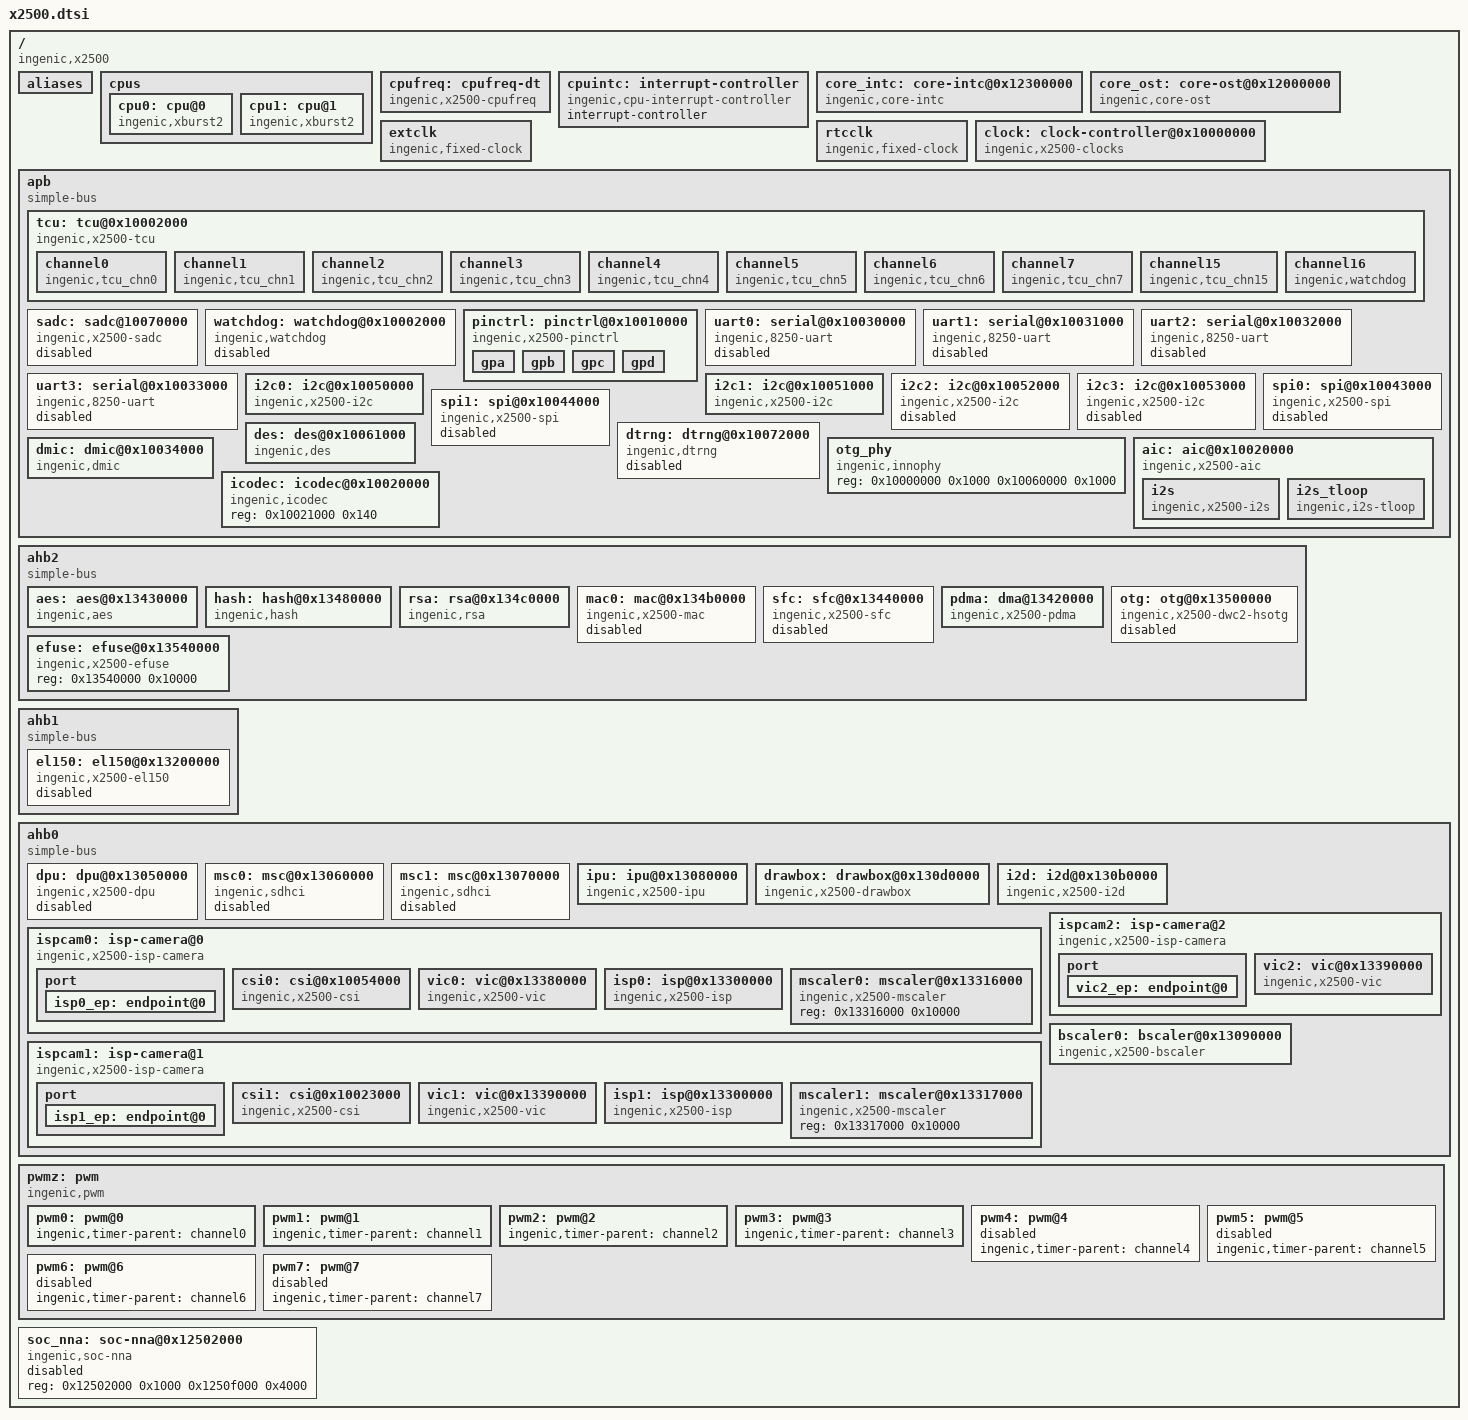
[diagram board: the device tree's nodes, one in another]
#include <dt-bindings/interrupt-controller/x2500-irq.h>
#include <dt-bindings/clock/ingenic-x2500.h>
#include <dt-bindings/clock/ingenic-tcu.h>
#include <dt-bindings/sound/ingenic-baic.h>
#include <dt-bindings/net/ingenic_gmac.h>
#include <dt-bindings/dma/ingenic-pdma.h>

/ {
	#address-cells = <1>;
	#size-cells = <1>;
	compatible = "ingenic,x2500";

	aliases: aliases {
		i2c0 = &i2c0;
		i2c1 = &i2c1;
		i2c2 = &i2c2;
		i2c3 = &i2c3;
		uart0 = &uart0;
		uart1 = &uart1;
		uart2 = &uart2;
		uart3 = &uart3;
		mmc0 = &msc0;
		mmc1 = &msc1;
		mac0 = &mac0;
		spi0 = &spi0;
		spi1 = &spi1;
		bscaler0 = &bscaler0;
	};

	cpus: cpus {
		#address-cells = <1>;
		#size-cells = <0>;

		cpu0: cpu@0 {
			device_type = "cpu";
			compatible = "ingenic,xburst2";
			reg = <0x000>;
			clock-frequency = <1200000000>;
		};

		cpu1: cpu@1 {
			device_type = "cpu";
			compatible = "ingenic,xburst2";
			reg = <0x001>;
			clock-frequency = <1200000000>;
		};
	};

	cpufreq: cpufreq-dt {
		 compatible = "ingenic,x2500-cpufreq";
		 status = "okay";
	};

	cpuintc: interrupt-controller {
		#address-cells = <0>;
		#interrupt-cells = <1>;
		interrupt-controller;
		compatible = "ingenic,cpu-interrupt-controller";

	};

	core_intc: core-intc@0x12300000 {
		compatible = "ingenic,core-intc";
		reg = <0x12300000 0x1000>,
		    <0x10001000 0x1000>;
		interrupt-controller;
		#interrupt-cells = <1>;
		cpu-intc-map = <0 0x000>,
			           <1 0x100>;

		interrupt-parent = <&cpuintc>;
		interrupts = <CORE_INTC_IRQ>;
		interrupt-names ="intc";
	};

	core_ost: core-ost@0x12000000 {
		compatible = "ingenic,core-ost";
		reg = <0x12000000 0x10000>, /*Global ost*/
		      <0x12100000 0x10000>; /*Core ost*/
		interrupt-parent = <&cpuintc>;
		interrupt-names = "sys_ost";
		interrupts = <CORE_SYS_OST_IRQ>;
		cpu-ost-map = 	<0 0x000>,
			<1 0x100>;
	};

	extclk: extclk {
		compatible = "ingenic,fixed-clock";
		clock-output-names ="ext";
		#clock-cells = <0>;
		clock-frequency  = <24000000>;
	};

	rtcclk: rtcclk {
		compatible = "ingenic,fixed-clock";
		clock-output-names ="rtc_ext";
		#clock-cells = <0>;
		clock-frequency = <32768>;
    };

	clock: clock-controller@0x10000000 {
		compatible = "ingenic,x2500-clocks";
		reg = <0x10000000 0x100>;
		clocks = <&extclk>, <&rtcclk>;
		clock-names = "ext", "rtc_ext";
		#clock-cells = <1>;
		little-endian;
	};

	apb {
		compatible = "simple-bus";
		#address-cells = <1>;
		#size-cells = <1>;
		ranges = <>;
		tcu: tcu@0x10002000 {
				compatible = "ingenic,x2500-tcu";
				reg = <0x10002000 0x140>;
				interrupt-parent = <&core_intc>;
				interrupt-names = "tcu_int0", "tcu_int1", "tcu_int2";
				interrupts = <IRQ_TCU0 IRQ_TCU1 IRQ_TCU2>;
				interrupt-controller;
				status = "ok";

				channel0: channel0 {
					compatible = "ingenic,tcu_chn0";
					ingenic,channel-info = <CHANNEL_INFO(0, TCU_MODE1, PWM_FUNC, \
					NO_PWM_IN,NOWORK_SLEEP)>;
				};
				channel1: channel1 {
					compatible = "ingenic,tcu_chn1";
					ingenic,channel-info = <CHANNEL_INFO(1, TCU_MODE2, PWM_FUNC, \
					NO_PWM_IN,NOWORK_SLEEP)>;
				};
				channel2: channel2 {
					compatible = "ingenic,tcu_chn2";
					ingenic,channel-info = <CHANNEL_INFO(2, TCU_MODE2, PWM_FUNC, \
					NO_PWM_IN,NOWORK_SLEEP)>;
				};
				channel3: channel3 {
					compatible = "ingenic,tcu_chn3";
					ingenic,channel-info = <CHANNEL_INFO(3, TCU_MODE1, \
					PWM_FUNC, NO_PWM_IN,NOWORK_SLEEP)>;
				};
				channel4: channel4 {
					compatible = "ingenic,tcu_chn4";
					ingenic,channel-info = <CHANNEL_INFO(4, TCU_MODE1, \
					PWM_FUNC, NO_PWM_IN,NOWORK_SLEEP)>;
				};
				channel5: channel5 {
					compatible = "ingenic,tcu_chn5";
					ingenic,channel-info = <CHANNEL_INFO(5, TCU_MODE1, \
					PWM_FUNC, NO_PWM_IN,NOWORK_SLEEP)>;
				};
				channel6: channel6 {
					compatible = "ingenic,tcu_chn6";
					ingenic,channel-info = <CHANNEL_INFO(6, TCU_MODE1, \
					PWM_FUNC, NO_PWM_IN,NOWORK_SLEEP)>;
				};
				channel7: channel7 {
					compatible = "ingenic,tcu_chn7";
					ingenic,channel-info = <CHANNEL_INFO(7, TCU_MODE1, \
					PWM_FUNC, NO_PWM_IN,NOWORK_SLEEP)>;
				};
				channel15: channel15 {
					compatible = "ingenic,tcu_chn15";
					ingenic,channel-info = <CHANNEL_INFO(15, 0,0,0,NOWORK_SLEEP)>;
				};
				channel16: channel16 {
					compatible = "ingenic,watchdog";
					ingenic,channel-info = <CHANNEL_INFO(16, 0,0,0,NOWORK_SLEEP)>;
				};
		};

        sadc: sadc@10070000 {
			compatible = "ingenic,x2500-sadc";
			reg = <0x10070000 0x32>;
			interrupt-parent = <&core_intc>;
			interrupts = <IRQ_SADC>;
			interrupt-controller;
			status = "disabled";
		};

		watchdog: watchdog@0x10002000 {
			compatible = "ingenic,watchdog";
			reg = <0x10002000 0x40>;
			interrupt-parent = <&core_intc>;
			interrupts = <IRQ_TCU0>;
			status = "disabled";
		};

		pinctrl: pinctrl@0x10010000 {
			compatible = "ingenic,x2500-pinctrl";
			reg = <0x10010000 0x1000>;
			ingenic,num-chips = <4>;
			ingenic,regs-offset = <0x1000>;

			gpa: gpa {
				gpio-controller;
				#gpio-cells = <3>;
				#ingenic,pincfg-cells = <3>;
				#ingenic,pinmux-cells = <2>;
				interrupts = <IRQ_GPIO0>;
				interrupt-parent = <&core_intc>;
				interrupt-controller;
				#interrupt-cells = <2>;
			};

			gpb: gpb {
				gpio-controller;
				#gpio-cells = <3>;
				#ingenic,pincfg-cells = <3>;
				#ingenic,pinmux-cells = <2>;
				interrupts = <IRQ_GPIO1>;
				interrupt-parent = <&core_intc>;
				interrupt-controller;
				#interrupt-cells = <2>;
			};

			gpc: gpc {
				gpio-controller;
				#gpio-cells = <3>;
				#ingenic,pincfg-cells = <3>;
				#ingenic,pinmux-cells = <2>;
				interrupts = <IRQ_GPIO2>;
				interrupt-parent = <&core_intc>;
				interrupt-controller;
				#interrupt-cells = <2>;
			};

			gpd: gpd {
				gpio-controller;
				#gpio-cells = <3>;
				#ingenic,pincfg-cells = <3>;
				#ingenic,pinmux-cells = <2>;
				interrupts = <IRQ_GPIO3>;
				interrupt-parent = <&core_intc>;
				interrupt-controller;
				#interrupt-cells = <2>;
			};

		};

		uart0: serial@0x10030000 {
			compatible = "ingenic,8250-uart";
			reg = <0x10030000 0x1000>;
			reg-shift = <2>;
			interrupt-parent = <&core_intc>;
			interrupts = <IRQ_UART0>;
			pinctrl-names = "default";
			pinctrl-0 = <&uart0_pc>;
			status = "disabled";
		};
		uart1: serial@0x10031000 {
			compatible = "ingenic,8250-uart";
			reg = <0x10031000 0x1000>;
			reg-shift = <2>;
			interrupt-parent = <&core_intc>;
			interrupts = <IRQ_UART1>;
			pinctrl-names = "default";
			pinctrl-0 = <&uart1_pb>;
			status = "disabled";
		};
		uart2: serial@0x10032000 {
			compatible = "ingenic,8250-uart";
			reg = <0x10032000 0x1000>;
			reg-shift = <2>;
			interrupt-parent = <&core_intc>;
			interrupts = <IRQ_UART2>;
			pinctrl-names = "default";
			pinctrl-0 = <&uart2_pc>;
			status = "disabled";
		};
		uart3: serial@0x10033000 {
			compatible = "ingenic,8250-uart";
			reg = <0x10033000 0x1000>;
			reg-shift = <2>;
			interrupt-parent = <&core_intc>;
			interrupts = <IRQ_UART3>;
			pinctrl-names = "default";
			pinctrl-0 = <&uart3_pc>;
			status = "disabled";
		};

		i2c0: i2c@0x10050000 {
			compatible = "ingenic,x2500-i2c";
			reg = <0x10050000 0x1000>;
			interrupt-parent = <&core_intc>;
			interrupts = <IRQ_I2C0>;
			#address-cells = <1>;
			#size-cells = <0>;
			status = "okay";
		};

		i2c1: i2c@0x10051000 {
			compatible = "ingenic,x2500-i2c";
			reg = <0x10051000 0x1000>;
			interrupt-parent = <&core_intc>;
			interrupts = <IRQ_I2C1>;
			#address-cells = <1>;
			#size-cells = <0>;
			status = "okay";
		};

		i2c2: i2c@0x10052000 {
			compatible = "ingenic,x2500-i2c";
			reg = <0x10052000 0x1000>;
			interrupt-parent = <&core_intc>;
			interrupts = <IRQ_I2C2>;
			#address-cells = <1>;
			#size-cells = <0>;
			status = "disabled";
		};

		i2c3: i2c@0x10053000 {
			compatible = "ingenic,x2500-i2c";
			reg = <0x10053000 0x1000>;
			interrupt-parent = <&core_intc>;
			interrupts = <IRQ_I2C3>;
			#address-cells = <1>;
			#size-cells = <0>;
			status = "disabled";
		};

		spi0: spi@0x10043000 {
			compatible = "ingenic,x2500-spi";
			reg = <0x10043000 0x1000>;
			interrupt-parent = <&core_intc>;
			interrupts = <IRQ_SSI0>;
			dmas = <&pdma INGENIC_DMA_TYPE(INGENIC_DMA_REQ_SSI0_TX)>,
				   <&pdma INGENIC_DMA_TYPE(INGENIC_DMA_REQ_SSI0_RX)>;
			dma-names = "tx", "rx";
			#address-cells = <1>;
			#size-cells = <0>;
			status = "disabled";
		};

		spi1: spi@0x10044000 {
			compatible = "ingenic,x2500-spi";
			reg = <0x10044000 0x1000>;
			interrupt-parent = <&core_intc>;
			interrupts = <IRQ_SSI1>;
			dmas = <&pdma INGENIC_DMA_TYPE(INGENIC_DMA_REQ_SSI1_TX)>,
				   <&pdma INGENIC_DMA_TYPE(INGENIC_DMA_REQ_SSI1_RX)>;
			dma-names = "tx", "rx";
			#address-cells = <1>;
			#size-cells = <0>;
			status = "disabled";
		};

		dtrng: dtrng@0x10072000 {
			compatible = "ingenic,dtrng";
			reg = <0x10072000 0x100>;
			interrupt-parent = <&core_intc>;
			interrupts = <IRQ_DTRNG>;
			status = "disabled";
		};

		des: des@0x10061000 {
			compatible = "ingenic,des";
			reg = <0x10043000 0x1000>;
			dmas = <&pdma INGENIC_DMA_TYPE(INGENIC_DMA_REQ_DES_TX)>,
				   <&pdma INGENIC_DMA_TYPE(INGENIC_DMA_REQ_DES_RX)>;
			dma-names = "tx", "rx";
			#address-cells = <1>;
			#size-cells = <0>;
			status = "okay";
		};

		otg_phy: otg_phy {
			compatible = "ingenic,innophy";
			reg = <0x10000000 0x1000 0x10060000 0x1000>;
		};

		aic: aic@0x10020000 {
			compatible = "ingenic,x2500-aic";
			reg = <0x10020000 0x100>;
			interrupt-parent = <&core_intc>;
			interrupts = <IRQ_AIC0>;
			dmas = <&pdma INGENIC_DMA_TYPE(INGENIC_DMA_REQ_I2S_TX)>,
				   <&pdma INGENIC_DMA_TYPE(INGENIC_DMA_REQ_I2S_RX)>;
			dma-names = "tx", "rx";
			i2s: i2s {
				compatible = "ingenic,x2500-i2s";
				status = "ok";
			};
			i2s_tloop: i2s_tloop {
				compatible = "ingenic,i2s-tloop";
				dmas = <&pdma INGENIC_DMA_TYPE(INGENIC_DMA_REQ_AIC_LOOP_RX)>;
				dma-names = "rx";
				status = "ok";
			};
		};

		dmic: dmic@0x10034000 {
			compatible = "ingenic,dmic";
			reg = <0x10034000 0x100>;
			interrupt-parent = <&core_intc>;
			interrupts = <IRQ_DMIC>;
			dmas = <&pdma INGENIC_DMA_TYPE(INGENIC_DMA_REQ_DMIC_RX)>;
			dma-names = "rx";
			pinctrl-0 = <&dmic0_pc>;
			pinctrl-names = "default";
			status = "ok";
		};
		icodec: icodec@0x10020000 {
			compatible = "ingenic,icodec";
			reg = <0x10021000 0x140>;
			status = "okay";
		};

	};

	ahb2 {
		compatible = "simple-bus";
		#address-cells = <1>;
		#size-cells = <1>;
		ranges = <>;

		aes: aes@0x13430000 {
			compatible = "ingenic,aes";
			reg = <0x13430000 0x10000>;
			interrupt-parent = <&core_intc>;
			interrupts = <IRQ_AES>;
			status = "okay";
		};

		hash: hash@0x13480000 {
			compatible = "ingenic,hash";
			reg = <0x13480000 0x10000>;
			interrupt-parent = <&core_intc>;
			interrupts = <IRQ_HASH>;
			status = "okay";
		};

		rsa: rsa@0x134c0000 {
			compatible = "ingenic,rsa";
			reg = <0x134c0000 0x10000>;
			interrupt-parent = <&core_intc>;
			interrupts = <IRQ_RSA>;
			status = "okay";
		};

		mac0: mac@0x134b0000 {
			compatible = "ingenic,x2500-mac";
			reg = <0x134b0000 0x2000>;
			interrupt-parent = <&core_intc>;
			interrupts = <IRQ_GMAC0>;
			status = "disabled";
			ingenic,rst-ms = <10>;
		};

		sfc: sfc@0x13440000 {
			compatible = "ingenic,x2500-sfc";
			reg = <0x13440000 0x10000>;
			interrupt-parent = <&core_intc>;
			interrupts = <IRQ_SFC>;
			pinctrl-names = "default";
			pinctrl-0 = <&sfc_pa>;
			status = "disabled";
		};

		pdma: dma@13420000 {
			compatible = "ingenic,x2500-pdma";
			reg = <0x13420000 0x10000>;
			interrupt-parent = <&core_intc>;
			interrupt-names = "pdma", "pdmam";
			interrupts = <IRQ_PDMA>, <IRQ_PDMAM>;
			#dma-channels = <32>;
			#dma-cells = <1>;
			ingenic,reserved-chs = <0x3>;
		};

		otg: otg@0x13500000 {
			compatible = "ingenic,x2500-dwc2-hsotg";
			reg = <0x13500000 0x40000>;
			interrupt-parent = <&core_intc>;
			interrupts = <IRQ_OTG>;
			ingenic,usbphy=<&otg_phy>;

			g-rx-fifo-size = <1096>;
			g-np-tx-fifo-size = <512>;
			g-tx-fifo-size = <16 16 16 128 256 256 512 768>;
			status = "disabled";
		};

		efuse: efuse@0x13540000 {
			compatible = "ingenic,x2500-efuse";
			reg = <0x13540000 0x10000>;
			status = "okay";
		};
	};

	ahb1 {
		compatible = "simple-bus";
		#address-cells = <1>;
		#size-cells = <1>;
		ranges = <>;

        el150: el150@0x13200000 {
			compatible = "ingenic,x2500-el150";
			reg = <0x13200000 0x100000>;
			interrupt-parent = <&core_intc>;
			interrupts = <IRQ_EL150>;
			status = "disabled";
		};

	};

	ahb0 {
		compatible = "simple-bus";
		#address-cells = <1>;
		#size-cells = <1>;
		ranges = <>;

		dpu: dpu@0x13050000 {
			compatible = "ingenic,x2500-dpu";
			reg = <0x13050000 0x10000>;
			interrupt-parent = <&core_intc>;
			interrupts = <IRQ_LCD>;
			status = "disabled";
		};

		msc0: msc@0x13060000 {
			compatible = "ingenic,sdhci";
			reg = <0x13060000 0x10000>;
			status = "disabled";
			interrupt-parent = <&core_intc>;
			interrupts = <IRQ_MSC0>;
			pinctrl-names ="default";
			pinctrl-0 = <&msc0_4bit>;
		};

		msc1: msc@0x13070000 {
			compatible = "ingenic,sdhci";
			reg = <0x13070000 0x10000>;
			status = "disabled";
			interrupt-parent = <&core_intc>;
			interrupts = <IRQ_MSC1>;
			pinctrl-names ="default";
			pinctrl-0 = <&msc1_4bit>;
		};

		ipu: ipu@0x13080000 {
			compatible = "ingenic,x2500-ipu";
			reg = <0x13080000 0x10000>;
			interrupt-parent = <&core_intc>;
			interrupts = <IRQ_IPU>;
			status = "okay";
		};

		drawbox: drawbox@0x130d0000 {
			 compatible = "ingenic,x2500-drawbox";
			 reg = <0x130d0000 0x10000>;
			 interrupt-parent = <&core_intc>;
			 interrupts = <IRQ_DRAW_BOX>;
			 status = "okay";
		};

        i2d: i2d@0x130b0000 {
			compatible = "ingenic,x2500-i2d";
			reg = <0x130b0000 0x10000>;
			interrupt-parent = <&core_intc>;
			interrupts = <IRQ_I2D>;
			status = "okay";
		};

		ispcam0: isp-camera@0 {
			compatible = "ingenic,x2500-isp-camera";
			#address-cells = <1>;
			#size-cells = <1>;
			ranges = <>;

			port {
				isp0_ep:endpoint@0 {

				};
			};


			csi0: csi@0x10054000 {
				compatible = "ingenic,x2500-csi";
				reg = <0x10054000 0x1000>;
				clocks = <&clock CLK_GATE_MIPI_CSI>;
				clock-names = "gate_csi";
			};

			vic0: vic@0x13380000 {
				compatible = "ingenic,x2500-vic";
				reg = <0x13380000 0x10000>;
				interrupt-parent = <&core_intc>;
				interrupts = <IRQ_S0_VIC>;
				status = "ok";
			};
			isp0: isp@0x13300000 {
				compatible = "ingenic,x2500-isp";
				clocks = <&clock CLK_DIV_ISP>, <&clock CLK_GATE_ISP>;
				clock-names = "gate_isp", "div_isp";
				status = "ok";
				ingenic,cpm_reset = <0xb00000c4>;
				ingenic,bit_sr = <22>;
				ingenic,bit_stp = <21>;
				ingenic,bit_ack = <20>;
				ingenic,index = <0>;
			};

			mscaler0: mscaler@0x13316000 {
				compatible = "ingenic,x2500-mscaler";
				reg = <0x13316000 0x10000>;
				status = "ok";
			};


		};

		ispcam1: isp-camera@1 {
			compatible = "ingenic,x2500-isp-camera";
			#address-cells = <1>;
			#size-cells = <1>;
			ranges = <>;

			port {
				isp1_ep:endpoint@0 {

				};
			};


			csi1: csi@0x10023000 {
				compatible = "ingenic,x2500-csi";
				reg = <0x10023000 0x1000>;
				clocks = <&clock CLK_GATE_MIPI_CSI>;
				clock-names = "gate_csi";
			};

			vic1: vic@0x13390000 {
				compatible = "ingenic,x2500-vic";
				reg = <0x13390000 0x10000>;
				interrupt-parent = <&core_intc>;
				interrupts = <IRQ_S1_VIC>;
				status = "ok";
			};

			isp1: isp@0x13300000 {
				compatible = "ingenic,x2500-isp";
				clocks = <&clock CLK_DIV_ISP>, <&clock CLK_GATE_ISP>;
				clock-names = "gate_isp", "div_isp";
				status = "ok";
				ingenic,cpm_reset = <0xb00000c4>;
				ingenic,bit_sr = <22>;
				ingenic,bit_stp = <21>;
				ingenic,bit_ack = <20>;
				ingenic,index = <1>;
			};

			mscaler1: mscaler@0x13317000 {
				compatible = "ingenic,x2500-mscaler";
				reg = <0x13317000 0x10000>;
				status = "ok";
			};

		};

		ispcam2: isp-camera@2 {
			compatible = "ingenic,x2500-isp-camera";
			#address-cells = <1>;
			#size-cells = <1>;
			ranges = <>;

			port {
				vic2_ep:endpoint@0 {

				};
			};

			vic2: vic@0x13390000 {
				compatible = "ingenic,x2500-vic";
				reg = <0x133a0000 0x10000>;
				interrupt-parent = <&core_intc>;
				interrupts = <IRQ_S2_VIC>;
				status = "ok";
			};
		};


		bscaler0: bscaler@0x13090000 {
			compatible = "ingenic,x2500-bscaler";
			reg = <0x13090000 0x100>;
			interrupt-parent = <&core_intc>;
			interrupts = <IRQ_BSCALER0>,
                         <IRQ_BSCALER1>;
			status = "okay";
		};
	};
	pwmz:pwm {
		compatible = "ingenic,pwm";
		#pwm-cells = <2>;
		pinctrl-names = "default";
		pwm0:pwm@0 {
			ingenic,timer-parent = <&channel0>;
			status = "okay";
		};
		pwm1:pwm@1 {
			ingenic,timer-parent = <&channel1>;
			status = "okay";
		};
		pwm2:pwm@2 {
			ingenic,timer-parent = <&channel2>;
			status = "okay";
		};
		pwm3:pwm@3 {
			ingenic,timer-parent = <&channel3>;
			status = "okay";
		};
		pwm4:pwm@4 {
			ingenic,timer-parent = <&channel4>;
			status = "disabled";
		};
		pwm5:pwm@5 {
			ingenic,timer-parent = <&channel5>;
			status = "disabled";
		};
		pwm6:pwm@6 {
			ingenic,timer-parent = <&channel6>;
			status = "disabled";
		};
		pwm7:pwm@7 {
			ingenic,timer-parent = <&channel7>;
			status = "disabled";
		};
	};
	soc_nna:soc-nna@0x12502000 {
		compatible = "ingenic,soc-nna";
		#address-cells = <1>;
		#size-cells = <1>;
		reg = <0x12502000 0x1000 0x1250f000 0x4000>;
		status = "disable";
	};

};

#include "x2500-pinctrl.dtsi"
